# A31T41x register map
Vendor: ABOV Semiconductor Co., Ltd.; File version: 1.0
CPU: CM0PLUS r0p1, little endian, no MPU, no FPU, VTOR, vendor SysTick, 2 interrupt priority bits
Registers are 32-bit, read-write, reset 0x0 unless marked. A register's access mark holds for its fields unless they carry their own. Offsets are from the block's base; [hi:lo] are bit positions; {n}, {i} and the like mark numbered series; 'fields as' and 'values as' point back to an identical list.

## ADC — 12-BIT A/D CONVERTER
Base 0x40092000
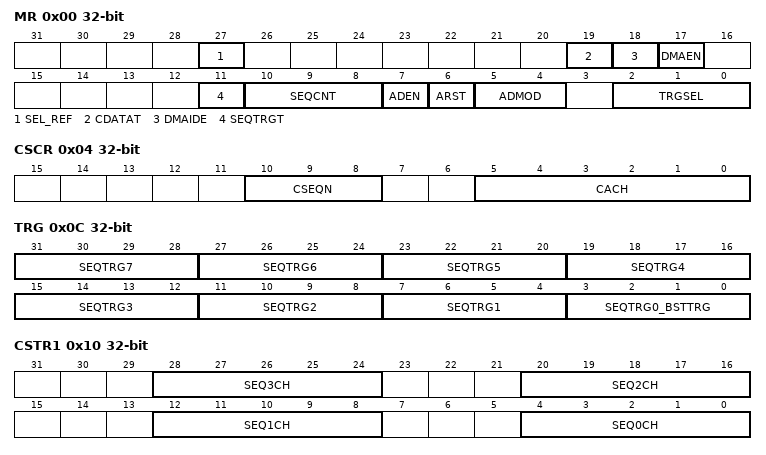
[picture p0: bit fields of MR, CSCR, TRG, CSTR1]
0x00 MR — ADC mode register
  [27] SEL_REF — SEL_REF control
    0=Disable (VDD); 1=Enable (AVREF)
  [19] CDATAT — Conversion data offset alignment
    0=Bit_15_4 (Data bit 15~4); 1=Bit_11_0 (Data bit 11~0)
  [18] DMAIDE — Wheter the DMA includes the injection data
    0=Disable (Dose not include); 1=Enable (Include)
  [17] DMAEN — DMA enable bit (This bit must be set if ADEN = 1.)
    0=Disable (DMA Disable); 1=Enable (DMA Enable)
  [11] SEQTRGT — Trigger pending type control in sequential mode
    0=Disable (Trigger that is not related current count in sequential is pending.); 1=Enable (Trigger that is not related current count in sequential is not pending.)
  [10:8] SEQCNT — Number of conversions in a sequence
  [7] ADEN — ADC enable bit
    0=Disable ADC; 1=Enable ADC
  [6] ARST — Setting bit to restart at the end of the sequence
    0=STOP (after ending, STOP); 1=RESTART (After ending, restart)
  [5:4] ADMOD — ADC mode selection bit
    0=Single_Sequencial (Single or Sequential conversion mode); 1=Burst conversion mode; 2=Multiple conversion mode
  [2:0] TRGSEL — Trigger selection bit
    0=Soft_TRG (event trigger disable / Software Trigger Only); 1=TIMER (TIMER event trigger / Software trigger)
0x04 CSCR — ADC current sequence/channel register
  [10:8] CSEQN ro — Current sequence number
    {v}=Sequence{v} (Current Sequence {v}) (v=0..7)
  [5:0] CACH ro — Current active channel
    {v}=CH{v} (ADC Channel active is {v}) (v=0..35); 36=CH36 (ADC Channel active is 36(BGREFADC_1V_S)); 37=CH37 (ADC Channel active is 37(VDD1P5V_IRC)); 38=CH38 (ADC Channel active is 38(VDD1P5V)); 39=CH39 (ADC Channel active is 39(Reserved))
0x08 CCR — ADC clock control register
  [14:8] CLKDIV — ADC clock division ratio value bit
0x0C TRG — ADC trigger select register
  [all] fields
    {v}=Source_{v} (TIMER {v}) (v=0..4); 15=Source_15 (ASTART)
  [4n+3:4n] SEQTRG{n} (n=1..7) — {n+1}th sequence trigger source
  [3:0] SEQTRG0_BSTTRG — 1th sequence trigger source, Burst conversion trigger source
0x10 CSTR1 — ADC Channel Selection Register 1
  [28:24] SEQ3CH — 4th conversion sequence channel sampling time
  [20:16] SEQ2CH — 3rd conversion sequence channel sampling time
  [12:8] SEQ1CH — 2nd conversion sequence channel sampling time
  [4:0] SEQ0CH — 1st conversion sequence channel sampling time
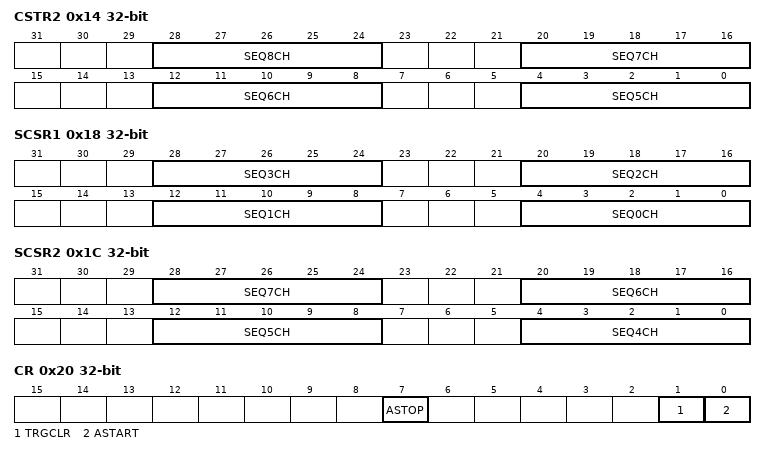
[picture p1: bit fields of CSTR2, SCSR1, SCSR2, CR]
0x14 CSTR2 — ADC Channel Selection Register 2
  [8n-36:8n-40] SEQ{n}CH (n=5..8) — {n}th conversion sequence channel sampling time
0x18 SCSR1 — ADC Channel Selection Register 1
  [28:24] SEQ3CH — 4th conversion sequence channel selection
  [20:16] SEQ2CH — 3rd conversion sequence channel selection
  [12:8] SEQ1CH — 2nd conversion sequence channel selection
  [4:0] SEQ0CH — 1st conversion sequence channel selection
0x1C SCSR2 — ADC Channel Selection Register 2
  [8n-28:8n-32] SEQ{n}CH (n=4..7) — {n+1}th conversion sequence channel selection
0x20 CR — ADC control register
  [7] ASTOP wo — ADC STOP bit
  [1] TRGCLR — ADC all trigger flags clear option
  [0] ASTART — ADC START Bit
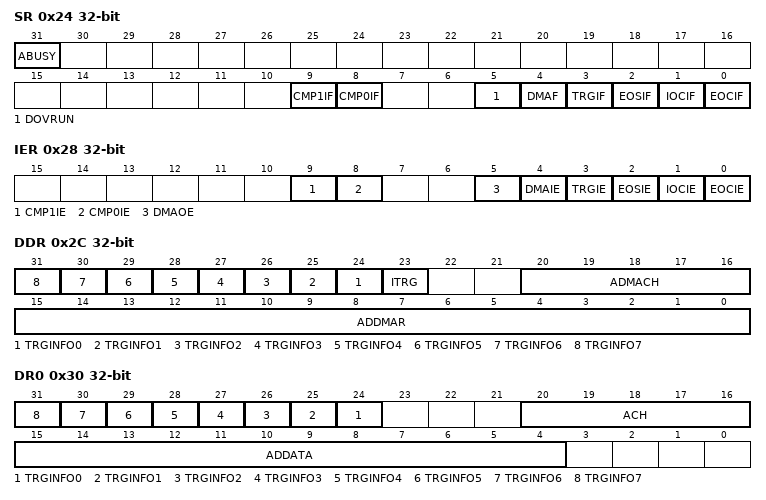
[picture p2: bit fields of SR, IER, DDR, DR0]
0x24 SR — ADC Status Register
  [31] ABUSY ro — ADC busy status
  [9] CMP1IF — Compare 1 interrupt flag bit
  [8] CMP0IF — Compare 0 interrupt flag bit
  [5] DOVRUN ro — DMA overrun flag
  [4] DMAF ro — DMA done received flag (DMA transfer is completed.)
  [3] TRGIF — ADC trigger interrupt flag
  [2] EOSIF — Sequence end interrupt flag
  [1] IOCIF — Injection conversion end interrupt flag
  [0] EOCIF — Sequence conversion end interrupt flag
0x28 IER — ADC Interrupt Enable Register
  [9] CMP1IE — Compare 1 event Interrupt Enable
    0=Disable (Compare 1 event Interrupt Disable); 1=Enable (Compare 1 event Interrupt Enable)
  [8] CMP0IE — Compare 0 event interrupt enable
    0=Disable (Compare 0 event Interrupt Disable); 1=Enable (Compare 0 event Interrupt Enable)
  [5] DMAOE — DMA Overrun Interrupt Enable
    0=Disable (DMA Overrun Interrupt Disable); 1=Enable (DMA Overrun Interrupt Enable)
  [4] DMAIE — DMA done interrupt enable
    0=Disable (DMA Interrupt Disable); 1=Enable (DMA Interrupt Enable)
  [3] TRGIE — ADC trigger conversion interrupt enable
    0=Disable (ADC Trigger Conversion Interrupt Disable); 1=Enable (ADC Trigger Conversion Interrupt Enable)
  [2] EOSIE — ADC sequence conversion interrupt enable
    0=Disable (ADC Sequence Conversion Interrupt Disable); 1=Enable (ADC Sequence Conversion Interrupt Enable)
  [1] IOCIE — Injection conversion end interrupt enable
    0=Disable (ADC Single Conversion Interrupt Disable); 1=Enable (ADC Single Conversion Interrupt Enable)
  [0] EOCIE — ADC single conversion interrupt
    values as IOCIE
0x2C DDR ro — ADC DMA data register
  [n+24] TRGINFO{n} (n=0..7) — ADC sequential number information
  [23] ITRG — Injection mode trigger information
  [20:16] ADMACH — DMA ADC channel indicator
  [15:0] ADDMAR — DMA ADC conversion result data (12-bit)
0x30 DR0 — ADC Data 0 register
  [n+24] TRGINFO{n} ro (n=0..7) — ADC sequential number information
  [20:16] ACH ro — ADC channel indicator
  [15:4] ADDATA ro — ADC conversion result data (12-bit)
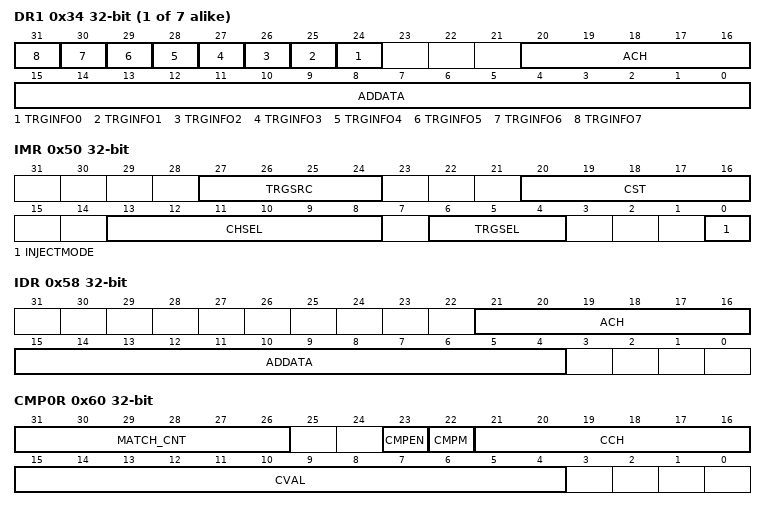
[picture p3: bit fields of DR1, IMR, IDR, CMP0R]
{0x30+4i} DR{i} (i=1..7) — ADC Data {i} register
  [n+24] TRGINFO{n} ro (n=0..7) — ADC sequential number information
  [20:16] ACH ro — ADC channel indicator
  [15:0] ADDATA ro — ADC conversion result data (12-bit)
0x50 IMR — The ADC_IMR register is used for ADC injection mode
  [27:24] TRGSRC ro — Trigger source selection bit
  [20:16] CST ro — Channel sampling time
  [13:8] CHSEL ro — Channel selection
  [6:4] TRGSEL ro — ADC sequential number information
    0=Disable (Event trigger disable / Soft trigger only); 2=Enable (Timer event trigger / Soft trigger)
  [0] INJECTMODE ro — Injection conversion mode enable bit
0x54 ICR — The ADC_ICR register is used to control the ADC injection
  [0] ASTART ro — ADC START bit
0x58 IDR — The ADC_IDR register is used for ADC injection data
  [21:16] ACH ro — ADC START bit
  [15:4] ADDATA — ADC input data
0x60 CMP0R — ADC Comparator 0 control Register
  [31:26] MATCH_CNT — Interrupt is generated only when ADC data compare data meets the condition (MATCHCNT+1) consecutively.
  [23] CMPEN — Compare operation enable bit
    0=Disable compare; 1=Enable compare
  [22] CMPM — ADC compare mode bit
    0=HIGHER (If ADC value is higher than CVAL value, compare output is high); 1=LOWER (If the ADC value is lower than the CVAL value, compare output is high)
  [21:16] CCH — Compare Channel
    {v}=CH{v} (ADC Channel {v}) (v=0..39)
  [15:4] CVAL — Compare value bit
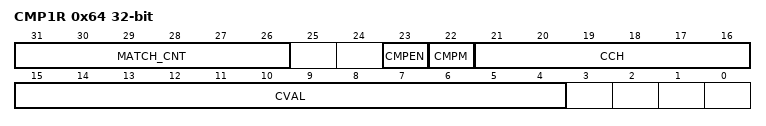
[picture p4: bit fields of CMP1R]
0x64 CMP1R — ADC Comparator 1 control Register
  [31:26] MATCH_CNT — Interrupt is generated only when ADC data compare data meets the condition (MATCHCNT+1) consecutively.
  [23] CMPEN — Compare operation enable bit
    0=Disable compare; 1=Enable compare
  [22] CMPM — ADC compare mode bit
    values as CMP0R.CMPM
  [21:16] CCH — Compare channel
    {v}=CH{v} (ADC Channel {v}) (v=0..39)
  [15:4] CVAL — Compare value bit
0x80 CDR0 — The ADC data register displays the result of ADC conversions
  [15:4] ADC_DATA ro — ADC conversion result data
